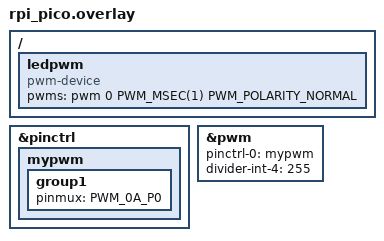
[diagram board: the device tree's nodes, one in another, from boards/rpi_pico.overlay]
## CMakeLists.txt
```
# SPDX-License-Identifier: Apache-2.0

cmake_minimum_required(VERSION 3.20.0)

find_package(Zephyr REQUIRED HINTS $ENV{ZEPHYR_BASE})
project(Test_PWM)

target_sources(app PRIVATE src/main.cpp)
include_directories(src)
include_directories(boards)
file(GLOB_RECURSE SRCS src/**.cpp)
target_sources(app PRIVATE ${SRCS})
```

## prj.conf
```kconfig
# nothing here
CONFIG_SERIAL=y
CONFIG_PINCTRL=y
CONFIG_PWM=y
CONFIG_PWM_LOG_LEVEL_DBG=y
CONFIG_I2C=y
CONFIG_GPIO=y
```

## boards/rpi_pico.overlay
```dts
/ {
    ledpwm: ledpwm {
        compatible = "pwm-device";
        status = "okay";
        pwms = <&pwm 0 PWM_MSEC(1) PWM_POLARITY_NORMAL>;
    };
};


&pinctrl{
    mypwm: mypwm {
        group1 {
            pinmux = <PWM_0A_P0>;
        };
    };
};

&pwm {
    pinctrl-0 = <&mypwm>;
    status = "okay";
    divider-int-4 = <255>;
};
```

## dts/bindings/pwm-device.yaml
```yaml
# Copyright (c) 2022 Nordic Semiconductor ASA
# SPDX-License-Identifier: Apache-2.0

description: PWM-driven device.
compatible: "pwm-device"
include: [ base.yaml ]

properties:
  pwms:
    required: true
    type: phandle-array
    description: PWM specifier driving the device.
```

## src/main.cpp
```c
#include <zephyr/kernel.h>
#include <zephyr/devicetree.h>
#include <zephyr/device.h>
#include <zephyr/drivers/pwm.h>
#include "drivers/lcd1602.hpp"
#include <cstdint>
#include <cstdio>
#include <string>

#define LED		DT_NODELABEL(ledpwm)
#define LCD     DT_NODELABEL(i2c0)

const struct pwm_dt_spec led = PWM_DT_SPEC_GET(LED);
//const struct device *lcd_dev = DEVICE_DT_GET(LCD);


#define NUM_STEPS	50U
#define SLEEP_MSEC	50U

int main()
{
	uint32_t pulse_width = 0U;
	uint32_t step = led.period / NUM_STEPS;
	uint8_t dir = 1U;
	int ret;

	/* lcdInit(lcd_dev);
    lcdClear(lcd_dev);
	char chn[3];
	snprintf(chn, 3, "%d", led.channel);
	lcdPutCur(lcd_dev, 0, 0);
	lcdSendString(lcd_dev, chn); */

	printk("PWM-based LED fade\n");

	if (!pwm_is_ready_dt(&led)) {
		printk("Error: PWM device %s is not ready\n",
		       led.dev->name);
		return 0;
	}

	while (1) {
/* 		ret = pwm_set_pulse_dt(&led, pulse_width);
		if (ret) {
			printk("Error %d: failed to set pulse width\n", ret);
			return 0;
		}

		if (dir) {
			pulse_width += step;
			if (pulse_width >= led.period) {
				pulse_width = led.period - step;
				dir = 0U;
			}
		} else {
			if (pulse_width >= step) {
				pulse_width -= step;
			} else {
				pulse_width = step;
				dir = 1U;
			}
		}

		k_sleep(K_MSEC(SLEEP_MSEC)); */
		pwm_set_pulse_dt(&led, pulse_width);
	}
	return 0;
}
```
